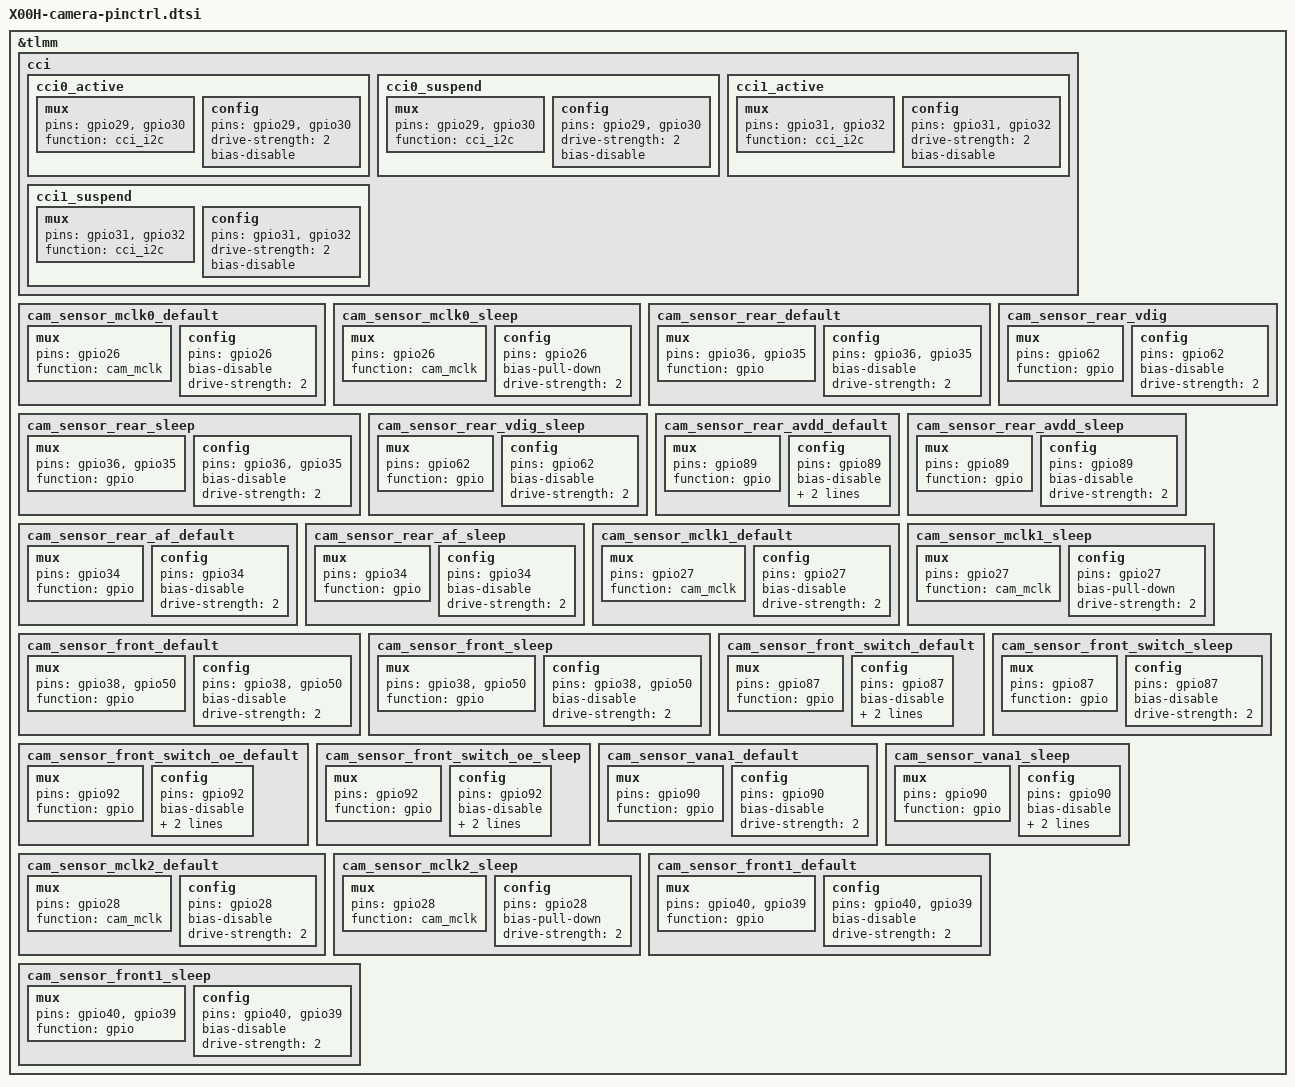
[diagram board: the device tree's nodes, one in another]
/*
 * Copyright (c) 2015-2018, The Linux Foundation. All rights reserved.
 *
 * This program is free software; you can redistribute it and/or modify
 * it under the terms of the GNU General Public License version 2 and
 * only version 2 as published by the Free Software Foundation.
 *
 * This program is distributed in the hope that it will be useful,
 * but WITHOUT ANY WARRANTY; without even the implied warranty of
 * MERCHANTABILITY or FITNESS FOR A PARTICULAR PURPOSE.  See the
 * GNU General Public License for more details.
 */

&tlmm {
	cci {
		cci0_active: cci0_active {
			mux {
				pins = "gpio29", "gpio30";
				function = "cci_i2c";
			};

			config {
				pins = "gpio29", "gpio30";
				drive-strength = <2>;
				bias-disable;
			};
		};

		cci0_suspend: cci0_suspend {
			mux {
				pins = "gpio29", "gpio30";
				function = "cci_i2c";
			};

			config {
				pins = "gpio29", "gpio30";
				drive-strength = <2>;
				bias-disable;
			};
		};

		cci1_active: cci1_active {
			mux {
				pins = "gpio31", "gpio32";
				function = "cci_i2c";
			};

			config {
				pins = "gpio31", "gpio32";
				drive-strength = <2>;
				bias-disable;
			};
		};

		cci1_suspend: cci1_suspend {
			mux {
				pins = "gpio31", "gpio32";
				function = "cci_i2c";
			};

			config {
				pins = "gpio31", "gpio32";
				drive-strength = <2>;
				bias-disable;
			};
		};
	};

	cam_sensor_mclk0_default: cam_sensor_mclk0_default {
		mux {
			pins = "gpio26";
			function = "cam_mclk";
		};

		config {
			pins = "gpio26";
			bias-disable;
			drive-strength = <2>;
		};
	};

	cam_sensor_mclk0_sleep: cam_sensor_mclk0_sleep {
		mux {
			pins = "gpio26";
			function = "cam_mclk";
		};

		config {
			pins = "gpio26";
			bias-pull-down;
			drive-strength = <2>;
		};
	};

	cam_sensor_rear_default: cam_sensor_rear_default {
		mux {
			pins = "gpio36", "gpio35";
			function = "gpio";
		};

		config {
			pins = "gpio36","gpio35";
			bias-disable;
			drive-strength = <2>;
		};
	};

	cam_sensor_rear_sleep: cam_sensor_rear_sleep {
		mux {
			pins = "gpio36","gpio35";
			function = "gpio";
		};

		config {
			pins = "gpio36","gpio35";
			bias-disable;
			drive-strength = <2>;
		};
	};

	cam_sensor_rear_vdig: cam_sensor_rear_vdig {
		mux {
			pins = "gpio62";
			function = "gpio";
		};

		config {
			pins = "gpio62";
			bias-disable;
			drive-strength = <2>;
		};
	};

	cam_sensor_rear_vdig_sleep: cam_sensor_rear_vdig_sleep {
		mux {
			pins = "gpio62";
			function = "gpio";
		};

		config {
			pins = "gpio62";
			bias-disable;
			drive-strength = <2>;
		};
	};

	cam_sensor_rear_avdd_default: cam_sensor_rear_avdd_default {
		mux {
			pins = "gpio89";
			function = "gpio";
		};

		config {
			pins = "gpio89";
			bias-disable;
			drive-strength = <2>;
			output-low;
		};
	};

	cam_sensor_rear_avdd_sleep: cam_sensor_rear_avdd_sleep {
		mux {
			pins = "gpio89";
			function = "gpio";
		};

		config {
			pins = "gpio89";
			bias-disable;
			drive-strength = <2>;
		};
	};

	cam_sensor_rear_af_default: cam_sensor_rear_af_default {
		mux {
			pins = "gpio34";
			function = "gpio";
		};

		config {
			pins = "gpio34";
			bias-disable;
			drive-strength = <2>;
		};
	};

	cam_sensor_rear_af_sleep: cam_sensor_rear_af_sleep {
		mux {
			pins = "gpio34";
			function = "gpio";
		};

		config {
			pins = "gpio34";
			bias-disable;
			drive-strength = <2>;
		};
	};

	cam_sensor_mclk1_default: cam_sensor_mclk1_default {
		mux {
			pins = "gpio27";
			function = "cam_mclk";
		};

		config {
			pins = "gpio27";
			bias-disable;
			drive-strength = <2>;
		};
	};

	cam_sensor_mclk1_sleep: cam_sensor_mclk1_sleep {
		mux {
			pins = "gpio27";
			function = "cam_mclk";
		};

		config {
			pins = "gpio27";
			bias-pull-down;
			drive-strength = <2>;
		};
	};

	cam_sensor_front_default: cam_sensor_front_default {
		mux {
			pins = "gpio38","gpio50";
			function = "gpio";
		};

		config {
			pins = "gpio38","gpio50";
			bias-disable;
			drive-strength = <2>;
		};
	};

	cam_sensor_front_sleep: cam_sensor_front_sleep {
		mux {
			pins = "gpio38","gpio50";
			function = "gpio";
		};

		config {
			pins = "gpio38","gpio50";
			bias-disable;
			drive-strength = <2>;
		};
	};

	cam_sensor_front_switch_default: cam_sensor_front_switch_default {
		mux {
			pins = "gpio87";
			function = "gpio";
		};

		config {
			pins = "gpio87";
			bias-disable;
			drive-strength = <2>;
			output-low;
		};
	};

	cam_sensor_front_switch_sleep: cam_sensor_front_switch_sleep {
		mux {
			pins = "gpio87";
			function = "gpio";
		};

		config {
			pins = "gpio87";
			bias-disable;
			drive-strength = <2>;
		};
	};

	cam_sensor_front_switch_oe_default: cam_sensor_front_switch_oe_default {
		mux {
			pins = "gpio92";
			function = "gpio";
		};

		config {
			pins = "gpio92";
			bias-disable;
			drive-strength = <2>;
			output-low;
		};
	};

	cam_sensor_front_switch_oe_sleep: cam_sensor_front_switch_oe_sleep {
		mux {
			pins = "gpio92";
			function = "gpio";
		};

		config {
			pins = "gpio92";
			bias-disable;
			drive-strength = <2>;
			output-low;
		};
	};

	cam_sensor_vana1_default:cam_sensor_vana1_default {
		mux {
			pins = "gpio90";
			function = "gpio";
		};

		config {
			pins = "gpio90";
			bias-disable;
			drive-strength = <2>;
		};
	};

	cam_sensor_vana1_sleep: cam_sensor_vana1_sleep {
		mux {
			pins = "gpio90";
			function = "gpio";
		};

		config {
			pins = "gpio90";
			bias-disable;
			drive-strength = <2>;
			output-low;
		};
	};

	cam_sensor_mclk2_default: cam_sensor_mclk2_default {
		mux {
			pins = "gpio28";
			function = "cam_mclk";
		};

		config {
			pins = "gpio28";
			bias-disable;
			drive-strength = <2>;
		};
	};

	cam_sensor_mclk2_sleep: cam_sensor_mclk2_sleep {
		mux {
			pins = "gpio28";
			function = "cam_mclk";
		};

		config {
			pins = "gpio28";
			bias-pull-down;
			drive-strength = <2>;
		};
	};

	cam_sensor_front1_default: cam_sensor_front1_default {
		mux {
			pins = "gpio40", "gpio39";
			function = "gpio";
		};

		config {
			pins = "gpio40", "gpio39";
			bias-disable;
			drive-strength = <2>;
		};
	};

	cam_sensor_front1_sleep: cam_sensor_front1_sleep {
		mux {
			pins = "gpio40", "gpio39";
			function = "gpio";
		};

		config {
			pins = "gpio40", "gpio39";
			bias-disable;
			drive-strength = <2>;
		};
	};
};
